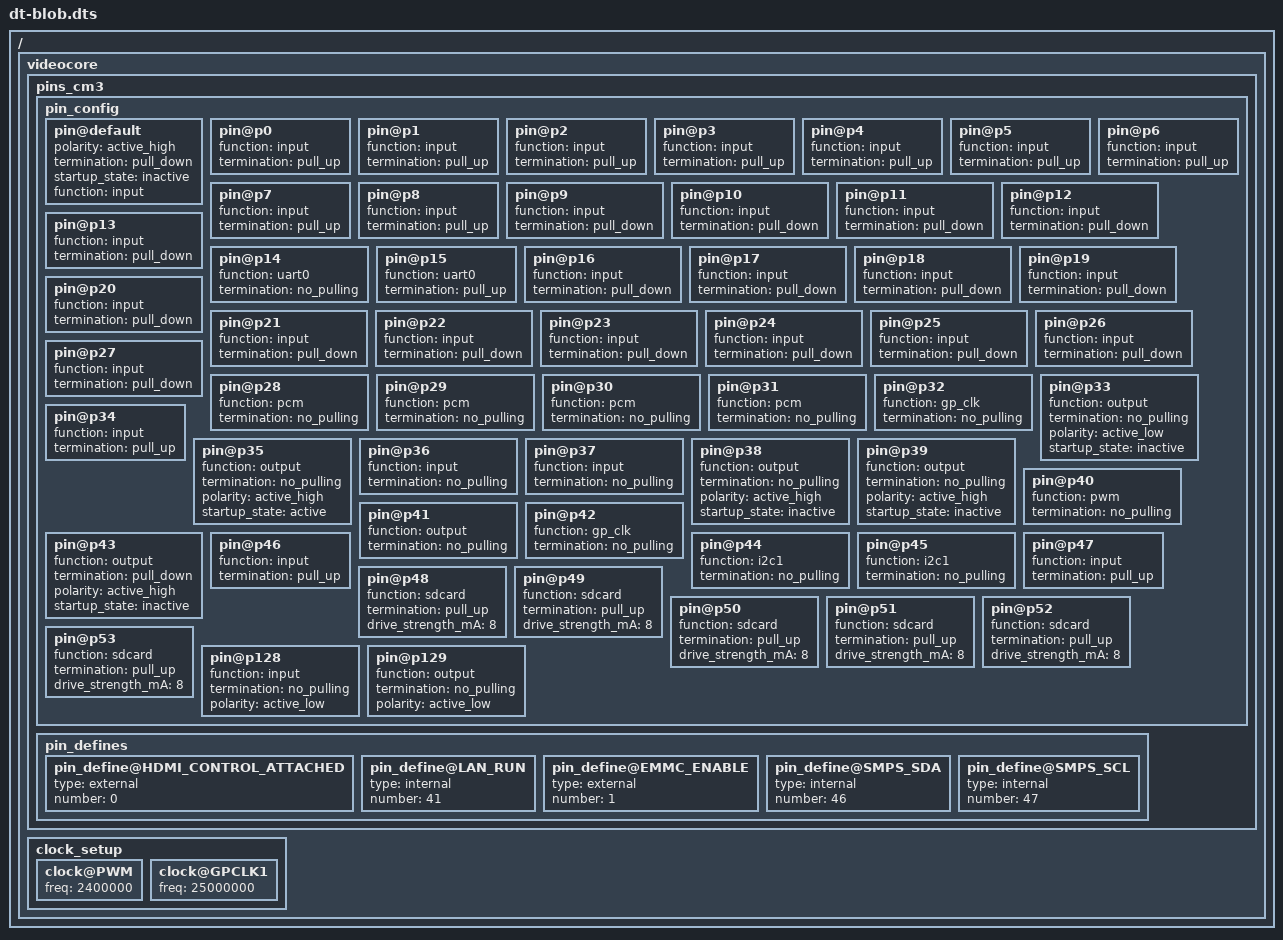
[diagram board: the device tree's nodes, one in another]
/dts-v1/;

/ {
  videocore {

    pins_cm3 {

      pin_config {

        pin@default {
          polarity = "active_high";
          termination = "pull_down";
          startup_state = "inactive";
          function = "input";
        }; // pin

        // BANK 0 //
        pin@p0  { function = "input";   termination = "pull_up";    }; // NOT USED (DEFAULT STATE)
        pin@p1  { function = "input";   termination = "pull_up";    }; // NOT USED (DEFAULT STATE)
        pin@p2  { function = "input";   termination = "pull_up";    }; // NOT USED (DEFAULT STATE)
        pin@p3  { function = "input";   termination = "pull_up";    }; // NOT USED (DEFAULT STATE)
        pin@p4  { function = "input";   termination = "pull_up";    }; // NOT USED (DEFAULT STATE)
        pin@p5  { function = "input";   termination = "pull_up";    }; // NOT USED (DEFAULT STATE)
        pin@p6  { function = "input";   termination = "pull_up";    }; // NOT USED (DEFAULT STATE)
        pin@p7  { function = "input";   termination = "pull_up";    }; // NOT USED (DEFAULT STATE)
        pin@p8  { function = "input";   termination = "pull_up";    }; // NOT USED (DEFAULT STATE)
        pin@p9  { function = "input";   termination = "pull_down";  }; // NOT USED (DEFAULT STATE)
        pin@p10 { function = "input";   termination = "pull_down";  }; // NOT USED (DEFAULT STATE)
        pin@p11 { function = "input";   termination = "pull_down";  }; // NOT USED (DEFAULT STATE)
        pin@p12 { function = "input";   termination = "pull_down";  }; // NOT USED (DEFAULT STATE)
        pin@p13 { function = "input";   termination = "pull_down";  }; // NOT USED (DEFAULT STATE)
        pin@p14 { function = "uart0";   termination = "no_pulling"; }; // UART0_TX
        pin@p15 { function = "uart0";   termination = "pull_up";    }; // UART0_RX
        pin@p16 { function = "input";   termination = "pull_down";  }; // NOT USED (DEFAULT STATE)
        pin@p17 { function = "input";   termination = "pull_down";  }; // NOT USED (DEFAULT STATE)
        pin@p18 { function = "input";   termination = "pull_down";  }; // NOT USED (DEFAULT STATE)
        pin@p19 { function = "input";   termination = "pull_down";  }; // NOT USED (DEFAULT STATE)
        pin@p20 { function = "input";   termination = "pull_down";  }; // NOT USED (DEFAULT STATE)
        pin@p21 { function = "input";   termination = "pull_down";  }; // NOT USED (DEFAULT STATE)
        pin@p22 { function = "input";   termination = "pull_down";  }; // NOT USED (DEFAULT STATE)
        pin@p23 { function = "input";   termination = "pull_down";  }; // NOT USED (DEFAULT STATE)
        pin@p24 { function = "input";   termination = "pull_down";  }; // NOT USED (DEFAULT STATE)
        pin@p25 { function = "input";   termination = "pull_down";  }; // NOT USED (DEFAULT STATE)
        pin@p26 { function = "input";   termination = "pull_down";  }; // NOT USED (DEFAULT STATE)
        pin@p27 { function = "input";   termination = "pull_down";  }; // NOT USED (DEFAULT STATE)

        // BANK 1 //
        pin@p28 { function = "pcm";     termination = "no_pulling"; }; // PCM_CLK
        pin@p29 { function = "pcm";     termination = "no_pulling"; }; // PCM_FS
        pin@p30 { function = "pcm";     termination = "no_pulling"; }; // PCM_DIN
        pin@p31 { function = "pcm";     termination = "no_pulling"; }; // PCM_DOUT
        pin@p32 { function = "gp_clk";  termination = "no_pulling"; }; // PCM_MCLK (GPCLK0)
        pin@p33 { function = "output";  termination = "no_pulling"; polarity = "active_low"; startup_state = "inactive"; }; // AUD_RST_N
        pin@p34 { function = "input";   termination = "pull_up";    }; // NOT USED
        pin@p35 { function = "output";  termination = "no_pulling"; polarity = "active_high"; startup_state = "active"; }; // USB_ON
        pin@p36 { function = "input";   termination = "no_pulling"; }; // RTC_IRQ
        pin@p37 { function = "input";   termination = "no_pulling"; }; // IR_RX
        pin@p38 { function = "output";  termination = "no_pulling"; polarity = "active_high"; startup_state = "inactive"; }; // STBY_LED
        pin@p39 { function = "output";  termination = "no_pulling"; polarity = "active_high"; startup_state = "inactive"; }; // DISK_OFF
        pin@p40 { function = "pwm";     termination = "no_pulling"; }; // LED_PWM
        pin@p41 { function = "output";  termination = "no_pulling"; }; // LAN_RUN
        pin@p42 { function = "gp_clk";  termination = "no_pulling"; }; // ETH_CLK (GPCLK1)
        pin@p43 { function = "output";  termination = "pull_down";  polarity = "active_high"; startup_state = "inactive"; }; // LEDS_ON
        pin@p44 { function = "i2c1";    termination = "no_pulling"; }; // SDA1
        pin@p45 { function = "i2c1";    termination = "no_pulling"; }; // SCL1

        // BANK 2 //
        pin@p46 { function = "input";   termination = "pull_up";    }; // SMPS_SCL
        pin@p47 { function = "input";   termination = "pull_up";    }; // SMPS_SDA
        pin@p48 { function = "sdcard";  termination = "pull_up";    drive_strength_mA = <8>; }; // SD CLK
        pin@p49 { function = "sdcard";  termination = "pull_up";    drive_strength_mA = <8>; }; // SD CMD
        pin@p50 { function = "sdcard";  termination = "pull_up";    drive_strength_mA = <8>; }; // SD D0
        pin@p51 { function = "sdcard";  termination = "pull_up";    drive_strength_mA = <8>; }; // SD D1
        pin@p52 { function = "sdcard";  termination = "pull_up";    drive_strength_mA = <8>; }; // SD D2
        pin@p53 { function = "sdcard";  termination = "pull_up";    drive_strength_mA = <8>; }; // SD D3
        pin@p128 { function = "input";  termination = "no_pulling"; polarity = "active_low"; }; // Hotplug
        pin@p129 { function = "output"; termination = "no_pulling"; polarity = "active_low"; }; // EMMC_ENABLE_N


      }; // pin_config

      pin_defines {
        pin_define@HDMI_CONTROL_ATTACHED { type = "external"; number = <0>; }; // HPD_N on external gpio
        pin_define@LAN_RUN { type = "internal"; number = <41>; }; // LAN_RUN
        pin_define@EMMC_ENABLE { type = "external"; number = <1>; };
        pin_define@SMPS_SDA { type = "internal"; number = <46>; };
        pin_define@SMPS_SCL { type = "internal"; number = <47>; };
      }; //  pin_defines

    }; // pins_cm

    clock_setup {
      clock@PWM    { freq = < 2400000>; }; // LEDS PWM CLOCK
      clock@GPCLK1 { freq = <25000000>; }; // ETH_CLK
    }; // clock_setup

  }; // videocore
};
